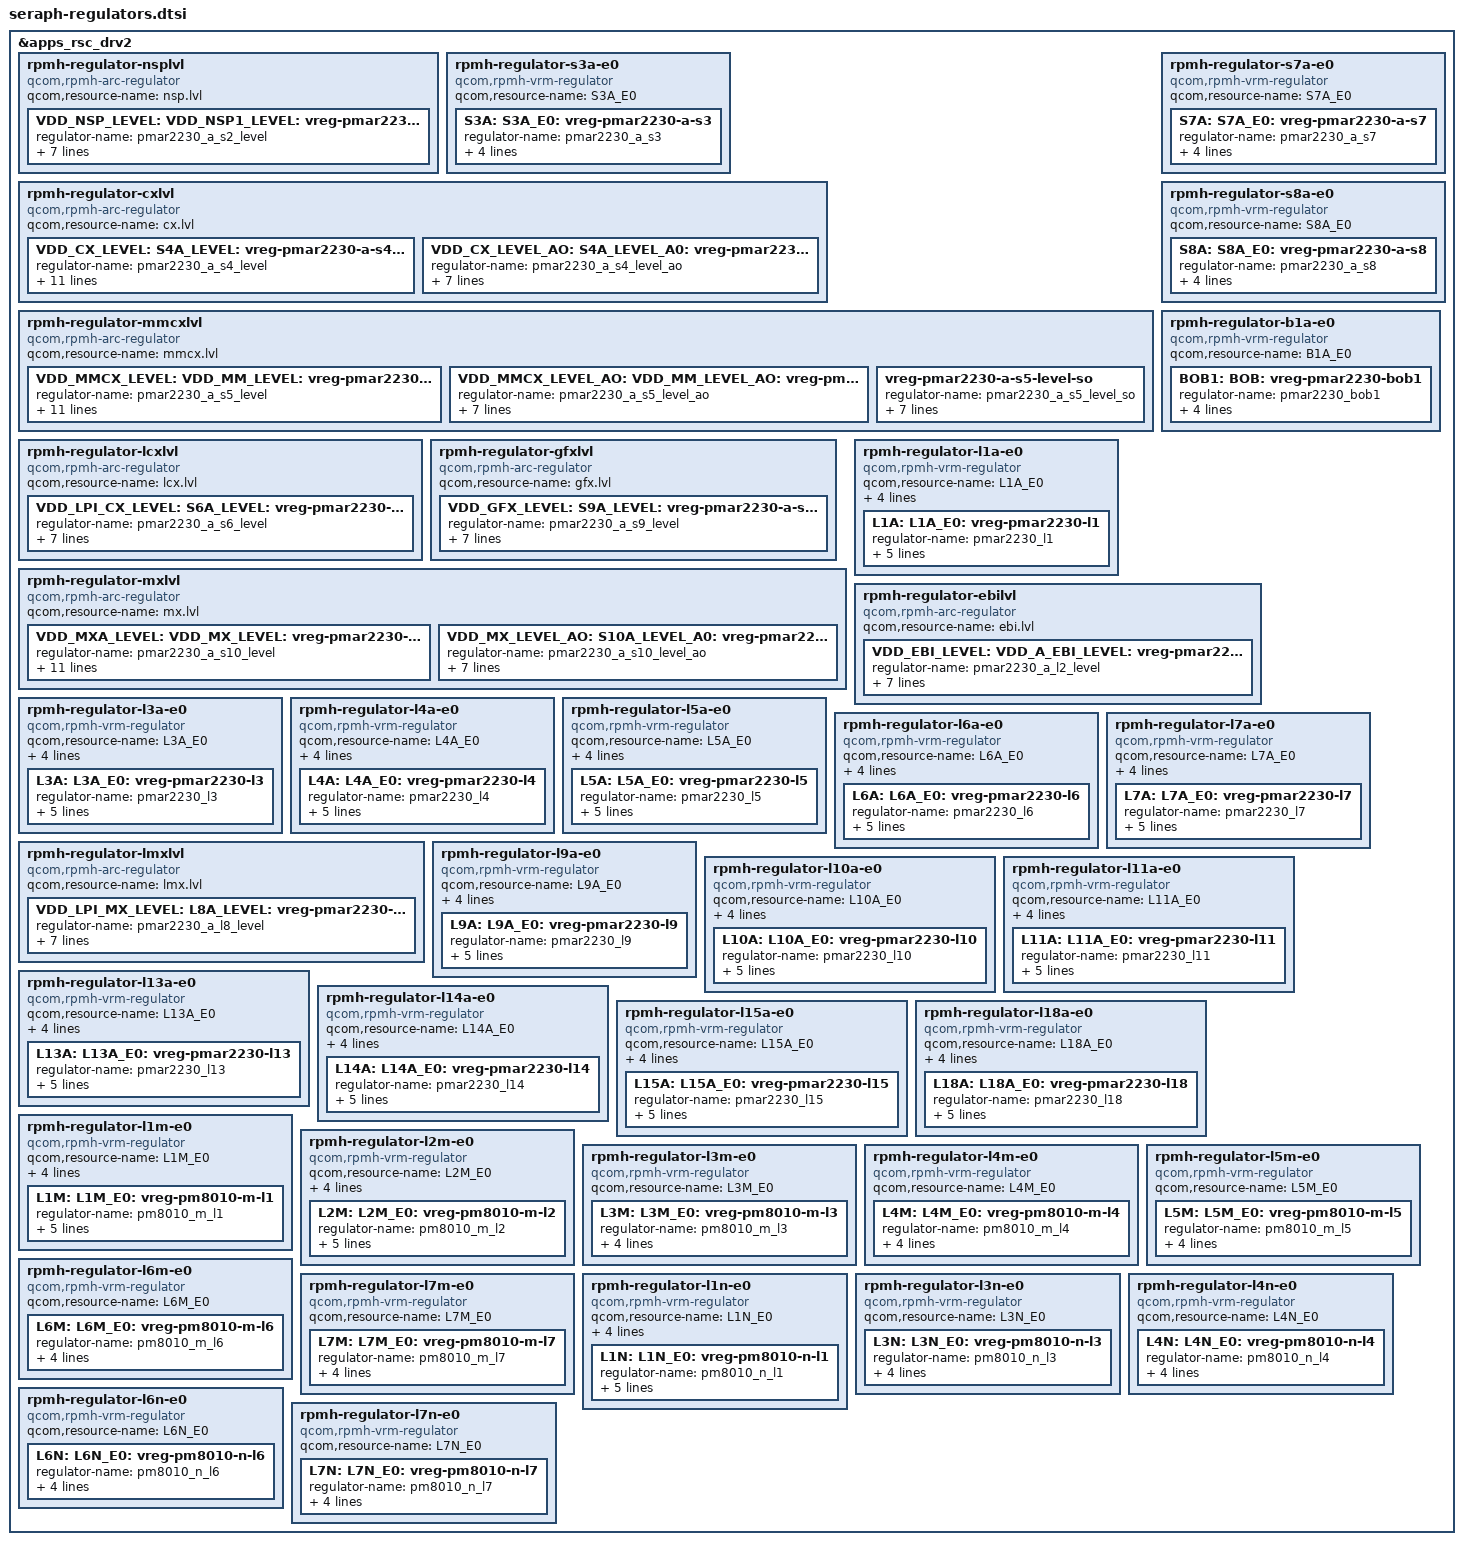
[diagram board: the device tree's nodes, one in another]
#include <dt-bindings/regulator/qcom,rpmh-regulator-levels.h>

&apps_rsc_drv2 {

	rpmh-regulator-nsplvl {
		compatible = "qcom,rpmh-arc-regulator";
		qcom,resource-name = "nsp.lvl";
		VDD_NSP_LEVEL:
		VDD_NSP1_LEVEL: S2A_LEVEL: S2A_E0_LEVEL:
		pmar2230_a_s2_level: vreg-pmar2230-a-s2-level {
			regulator-name = "pmar2230_a_s2_level";
			qcom,set = <RPMH_REGULATOR_SET_ALL>;
			regulator-min-microvolt =
				<RPMH_REGULATOR_LEVEL_RETENTION>;
			regulator-max-microvolt =
				<RPMH_REGULATOR_LEVEL_MAX>;
			qcom,init-voltage-level =
				<RPMH_REGULATOR_LEVEL_RETENTION>;
		};
	};

	rpmh-regulator-s3a-e0 {
		compatible = "qcom,rpmh-vrm-regulator";
		qcom,resource-name = "S3A_E0";
		S3A: S3A_E0:
		pmar2330_a_s3: vreg-pmar2230-a-s3 {
			regulator-name = "pmar2230_a_s3";
			qcom,set = <RPMH_REGULATOR_SET_ALL>;
			regulator-min-microvolt = <880000>;
			regulator-max-microvolt = <1080000>;
			qcom,init-voltage = <952000>;
		};
	};

	rpmh-regulator-cxlvl {
		compatible = "qcom,rpmh-arc-regulator";
		qcom,resource-name = "cx.lvl";
		VDD_CX_LEVEL:
		S4A_LEVEL: S4A_E0_LEVEL:
		pmar2230_a_s4_level: vreg-pmar2230-a-s4-level {
			regulator-name = "pmar2230_a_s4_level";
			qcom,set = <RPMH_REGULATOR_SET_ALL>;
			regulator-min-microvolt =
				<RPMH_REGULATOR_LEVEL_RETENTION>;
			regulator-max-microvolt =
				<RPMH_REGULATOR_LEVEL_MAX>;
			qcom,init-voltage-level =
				<RPMH_REGULATOR_LEVEL_TURBO>;
			proxy-supply = <&VDD_CX_LEVEL>;
			qcom,proxy-consumer-enable;
			qcom,proxy-consumer-voltage =
				<RPMH_REGULATOR_LEVEL_TURBO
				RPMH_REGULATOR_LEVEL_MAX>;
		};

		VDD_CX_LEVEL_AO:
		S4A_LEVEL_A0: S4A_E0_LEVEL_AO:
		pmar2230_a_s4_level_ao: vreg-pmar2230-a-s4-level-ao {
			regulator-name = "pmar2230_a_s4_level_ao";
			qcom,set = <RPMH_REGULATOR_SET_ACTIVE>;
			regulator-min-microvolt =
				<RPMH_REGULATOR_LEVEL_RETENTION>;
			regulator-max-microvolt =
				<RPMH_REGULATOR_LEVEL_MAX>;
			qcom,init-voltage-level =
				<RPMH_REGULATOR_LEVEL_RETENTION>;
		};
	};

	rpmh-regulator-mmcxlvl {
		compatible = "qcom,rpmh-arc-regulator";
		qcom,resource-name = "mmcx.lvl";
		VDD_MMCX_LEVEL: VDD_MM_LEVEL:
		S5A_LEVEL: S5A_E0_LEVEL:
		pmar2230_a_s5_level: vreg-pmar2230-a-s5-level {
			regulator-name = "pmar2230_a_s5_level";
			qcom,set = <RPMH_REGULATOR_SET_ALL>;
			regulator-min-microvolt =
				<RPMH_REGULATOR_LEVEL_LOW_SVS_D1>;
			regulator-max-microvolt =
				<RPMH_REGULATOR_LEVEL_MAX>;
			qcom,init-voltage-level =
				<RPMH_REGULATOR_LEVEL_TURBO>;
			proxy-supply = <&VDD_MMCX_LEVEL>;
			qcom,proxy-consumer-enable;
			qcom,proxy-consumer-voltage =
				<RPMH_REGULATOR_LEVEL_TURBO
				RPMH_REGULATOR_LEVEL_MAX>;
		};

		VDD_MMCX_LEVEL_AO: VDD_MM_LEVEL_AO:
		S5A_LEVEL_AO: S5A_E0_LEVEL_AO:
		pmar2230_a_s5_level_ao: vreg-pmar2230-a-s5-level-ao {
			regulator-name = "pmar2230_a_s5_level_ao";
			qcom,set = <RPMH_REGULATOR_SET_ACTIVE>;
			regulator-min-microvolt =
				<RPMH_REGULATOR_LEVEL_LOW_SVS_D1>;
			regulator-max-microvolt =
				<RPMH_REGULATOR_LEVEL_MAX>;
			qcom,init-voltage-level =
				<RPMH_REGULATOR_LEVEL_LOW_SVS_D1>;
		};

		vreg-pmar2230-a-s5-level-so {
			regulator-name = "pmar2230_a_s5_level_so";
			qcom,set = <RPMH_REGULATOR_SET_SLEEP>;
			regulator-min-microvolt =
				<RPMH_REGULATOR_LEVEL_LOW_SVS_D1>;
			regulator-max-microvolt =
				<RPMH_REGULATOR_LEVEL_MAX>;
			qcom,init-voltage-level =
				<RPMH_REGULATOR_LEVEL_LOW_SVS_D1>;
		};
	};

	rpmh-regulator-lcxlvl {
		compatible = "qcom,rpmh-arc-regulator";
		qcom,resource-name = "lcx.lvl";
		VDD_LPI_CX_LEVEL:
		S6A_LEVEL: S6A_E0_LEVEL:
		pmar2230_a_s6_level: vreg-pmar2230-a-s6-level {
			regulator-name = "pmar2230_a_s6_level";
			qcom,set = <RPMH_REGULATOR_SET_ALL>;
			regulator-min-microvolt =
				<RPMH_REGULATOR_LEVEL_RETENTION>;
			regulator-max-microvolt =
				<RPMH_REGULATOR_LEVEL_MAX>;
			qcom,init-voltage-level =
				<RPMH_REGULATOR_LEVEL_RETENTION>;
		};
	};

	rpmh-regulator-s7a-e0 {
		compatible = "qcom,rpmh-vrm-regulator";
		qcom,resource-name = "S7A_E0";
		S7A: S7A_E0:
		pmar2230_a_s7: vreg-pmar2230-a-s7 {
			regulator-name = "pmar2230_a_s7";
			qcom,set = <RPMH_REGULATOR_SET_ALL>;
			regulator-min-microvolt = <1852000>;
			regulator-max-microvolt = <2104000>;
			qcom,init-voltage = <1856000>;
		};
	};

	rpmh-regulator-s8a-e0 {
		compatible = "qcom,rpmh-vrm-regulator";
		qcom,resource-name = "S8A_E0";
		S8A: S8A_E0:
		pmar2230_a_s8: vreg-pmar2230-a-s8 {
			regulator-name = "pmar2230_a_s8";
			qcom,set = <RPMH_REGULATOR_SET_ALL>;
			regulator-min-microvolt = <1256000>;
			regulator-max-microvolt = <1408000>;
			qcom,init-voltage = <1304000>;
		};
	};

	rpmh-regulator-gfxlvl {
		compatible = "qcom,rpmh-arc-regulator";
		qcom,resource-name = "gfx.lvl";
		VDD_GFX_LEVEL:
		S9A_LEVEL: S9A_E0_LEVEL:
		pmar2230_a_s9_level: vreg-pmar2230-a-s9-level {
			regulator-name = "pmar2230_a_s9_level";
			qcom,set = <RPMH_REGULATOR_SET_ALL>;
			regulator-min-microvolt =
				<RPMH_REGULATOR_LEVEL_RETENTION>;
			regulator-max-microvolt =
				<RPMH_REGULATOR_LEVEL_MAX>;
			qcom,init-voltage-level =
				<RPMH_REGULATOR_LEVEL_RETENTION>;
		};
	};

	rpmh-regulator-mxlvl {
		compatible = "qcom,rpmh-arc-regulator";
		qcom,resource-name = "mx.lvl";
		VDD_MXA_LEVEL: VDD_MX_LEVEL:
		S10A_LEVEL: S10A_E0_LEVEL:
		pmar2230_a_s10_level: vreg-pmar2230-a-s10-level {
			regulator-name = "pmar2230_a_s10_level";
			qcom,set = <RPMH_REGULATOR_SET_ALL>;
			regulator-min-microvolt =
				<RPMH_REGULATOR_LEVEL_RETENTION>;
			regulator-max-microvolt =
				<RPMH_REGULATOR_LEVEL_MAX>;
			qcom,init-voltage-level =
				<RPMH_REGULATOR_LEVEL_TURBO>;
			proxy-supply = <&VDD_MXA_LEVEL>;
			qcom,proxy-consumer-enable;
			qcom,proxy-consumer-voltage =
				<RPMH_REGULATOR_LEVEL_TURBO
				RPMH_REGULATOR_LEVEL_MAX>;
		};

		VDD_MX_LEVEL_AO:
		S10A_LEVEL_A0: S10A_E0_LEVEL_AO:
		pmar2230_a_s10_level_ao: vreg-pmar2230-a-s10-level-ao {
			regulator-name = "pmar2230_a_s10_level_ao";
			qcom,set = <RPMH_REGULATOR_SET_ACTIVE>;
			regulator-min-microvolt =
				<RPMH_REGULATOR_LEVEL_RETENTION>;
			regulator-max-microvolt =
				<RPMH_REGULATOR_LEVEL_MAX>;
			qcom,init-voltage-level =
				<RPMH_REGULATOR_LEVEL_RETENTION>;
		};
	};

	rpmh-regulator-b1a-e0 {
		compatible = "qcom,rpmh-vrm-regulator";
		qcom,resource-name = "B1A_E0";

		BOB1: BOB: BOB1_E0: B1A_E0: pmar2230_bob1: vreg-pmar2230-bob1 {
			regulator-name = "pmar2230_bob1";
			qcom,set = <RPMH_REGULATOR_SET_ALL>;
			regulator-min-microvolt = <3008000>;
			regulator-max-microvolt = <3960000>;
			qcom,init-voltage = <3648000>;
		};
	};

	rpmh-regulator-l1a-e0 {
		compatible = "qcom,rpmh-vrm-regulator";
		qcom,resource-name = "L1A_E0";
		qcom,regulator-type = "pmic7-ldo";
		qcom,supported-modes =
			<RPMH_REGULATOR_MODE_LPM
			RPMH_REGULATOR_MODE_HPM>;
		qcom,mode-threshold-currents = <0 30000>;
		L1A: L1A_E0:
		pmar2230_l1: vreg-pmar2230-l1 {
			regulator-name = "pmar2230_l1";
			qcom,set = <RPMH_REGULATOR_SET_ALL>;
			regulator-min-microvolt = <320000>;
			regulator-max-microvolt = <570000>;
			qcom,init-voltage = <504000>;
			qcom,init-mode = <RPMH_REGULATOR_MODE_HPM>;
		};
	};

	rpmh-regulator-ebilvl {
		compatible = "qcom,rpmh-arc-regulator";
		qcom,resource-name = "ebi.lvl";
		VDD_EBI_LEVEL: VDD_A_EBI_LEVEL:
		L2A_LEVEL: L2A_E0_LEVEL:
		pmar2230_a_l2_level: vreg-pmar2230-a-l2-level {
			regulator-name = "pmar2230_a_l2_level";
			qcom,set = <RPMH_REGULATOR_SET_ALL>;
			regulator-min-microvolt =
				<RPMH_REGULATOR_LEVEL_RETENTION>;
			regulator-max-microvolt =
				<RPMH_REGULATOR_LEVEL_MAX>;
			qcom,init-voltage-level =
				<RPMH_REGULATOR_LEVEL_RETENTION>;
		};
	};

	rpmh-regulator-l3a-e0 {
		compatible = "qcom,rpmh-vrm-regulator";
		qcom,resource-name = "L3A_E0";
		qcom,regulator-type = "pmic7-ldo";
		qcom,supported-modes =
			<RPMH_REGULATOR_MODE_LPM
			RPMH_REGULATOR_MODE_HPM>;
		qcom,mode-threshold-currents = <0 30000>;
		L3A: L3A_E0:
		pmar2230_l3: vreg-pmar2230-l3 {
			regulator-name = "pmar2230_l3";
			qcom,set = <RPMH_REGULATOR_SET_ALL>;
			regulator-min-microvolt = <1080000>;
			regulator-max-microvolt = <2000000>;
			qcom,init-voltage = <1800000>;
			qcom,init-mode = <RPMH_REGULATOR_MODE_HPM>;
		};
	};

	rpmh-regulator-l4a-e0 {
		compatible = "qcom,rpmh-vrm-regulator";
		qcom,resource-name = "L4A_E0";
		qcom,regulator-type = "pmic7-ldo";
		qcom,supported-modes =
			<RPMH_REGULATOR_MODE_LPM
			RPMH_REGULATOR_MODE_AUTO>;
		qcom,mode-threshold-currents = <0 30000>;
		L4A: L4A_E0:
		pmar2230_l4: vreg-pmar2230-l4 {
			regulator-name = "pmar2230_l4";
			qcom,set = <RPMH_REGULATOR_SET_ALL>;
			regulator-min-microvolt = <1700000>;
			regulator-max-microvolt = <1950000>;
			qcom,init-voltage = <1800000>;
			qcom,init-mode = <RPMH_REGULATOR_MODE_HPM>;
		};
	};

	rpmh-regulator-l5a-e0 {
		compatible = "qcom,rpmh-vrm-regulator";
		qcom,resource-name = "L5A_E0";
		qcom,regulator-type = "pmic7-ldo";
		qcom,supported-modes =
			<RPMH_REGULATOR_MODE_LPM
			RPMH_REGULATOR_MODE_AUTO>;
		qcom,mode-threshold-currents = <0 30000>;
		L5A: L5A_E0:
		pmar2230_l5: vreg-pmar2230-l5 {
			regulator-name = "pmar2230_l5";
			qcom,set = <RPMH_REGULATOR_SET_ALL>;
			regulator-min-microvolt = <1080000>;
			regulator-max-microvolt = <1320000>;
			qcom,init-voltage = <1200000>;
			qcom,init-mode = <RPMH_REGULATOR_MODE_HPM>;
		};
	};

	rpmh-regulator-l6a-e0 {
		compatible = "qcom,rpmh-vrm-regulator";
		qcom,resource-name = "L6A_E0";
		qcom,regulator-type = "pmic7-ldo";
		qcom,supported-modes =
			<RPMH_REGULATOR_MODE_LPM
			RPMH_REGULATOR_MODE_AUTO>;
		qcom,mode-threshold-currents = <0 30000>;
		L6A: L6A_E0:
		pmar2230_l6: vreg-pmar2230-l6 {
			regulator-name = "pmar2230_l6";
			qcom,set = <RPMH_REGULATOR_SET_ALL>;
			regulator-min-microvolt = <1140000>;
			regulator-max-microvolt = <1260000>;
			qcom,init-voltage = <1200000>;
			qcom,init-mode = <RPMH_REGULATOR_MODE_HPM>;
		};
	};

	rpmh-regulator-l7a-e0 {
		compatible = "qcom,rpmh-vrm-regulator";
		qcom,resource-name = "L7A_E0";
		qcom,regulator-type = "pmic7-ldo";
		qcom,supported-modes =
			<RPMH_REGULATOR_MODE_LPM
			RPMH_REGULATOR_MODE_HPM>;
		qcom,mode-threshold-currents = <0 30000>;
		L7A: L7A_E0:
		pmar2230_l7: vreg-pmar2230-l7 {
			regulator-name = "pmar2230_l7";
			qcom,set = <RPMH_REGULATOR_SET_ALL>;
			regulator-min-microvolt = <1010000>;
			regulator-max-microvolt = <1120000>;
			qcom,init-voltage = <1080000>;
			qcom,init-mode = <RPMH_REGULATOR_MODE_HPM>;
		};
	};

	rpmh-regulator-lmxlvl {
		compatible = "qcom,rpmh-arc-regulator";
		qcom,resource-name = "lmx.lvl";
		VDD_LPI_MX_LEVEL:
		L8A_LEVEL: L8A_E0_LEVEL:
		pmar2230_a_l8_level: vreg-pmar2230-a-l8-level {
			regulator-name = "pmar2230_a_l8_level";
			qcom,set = <RPMH_REGULATOR_SET_ALL>;
			regulator-min-microvolt =
				<RPMH_REGULATOR_LEVEL_RETENTION>;
			regulator-max-microvolt =
				<RPMH_REGULATOR_LEVEL_MAX>;
			qcom,init-voltage-level =
				<RPMH_REGULATOR_LEVEL_RETENTION>;
		};
	};

	rpmh-regulator-l9a-e0 {
		compatible = "qcom,rpmh-vrm-regulator";
		qcom,resource-name = "L9A_E0";
		qcom,regulator-type = "pmic7-ldo";
		qcom,supported-modes =
			<RPMH_REGULATOR_MODE_LPM
			RPMH_REGULATOR_MODE_AUTO>;
		qcom,mode-threshold-currents = <0 30000>;
		L9A: L9A_E0:
		pmar2230_l9: vreg-pmar2230-l9 {
			regulator-name = "pmar2230_l9";
			qcom,set = <RPMH_REGULATOR_SET_ALL>;
			regulator-min-microvolt = <825000>;
			regulator-max-microvolt = <925000>;
			qcom,init-voltage = <880000>;
			qcom,init-mode = <RPMH_REGULATOR_MODE_HPM>;
		};
	};

	rpmh-regulator-l10a-e0 {
		compatible = "qcom,rpmh-vrm-regulator";
		qcom,resource-name = "L10A_E0";
		qcom,regulator-type = "pmic7-ldo";
		qcom,supported-modes =
			<RPMH_REGULATOR_MODE_LPM
			RPMH_REGULATOR_MODE_AUTO>;
		qcom,mode-threshold-currents = <0 30000>;
		L10A: L10A_E0:
		pmar2230_l10: vreg-pmar2230-l10 {
			regulator-name = "pmar2230_l10";
			qcom,set = <RPMH_REGULATOR_SET_ALL>;
			regulator-min-microvolt = <720000>;
			regulator-max-microvolt = <950000>;
			qcom,init-voltage = <880000>;
			qcom,init-mode = <RPMH_REGULATOR_MODE_HPM>;
		};
	};

	rpmh-regulator-l11a-e0 {
		compatible = "qcom,rpmh-vrm-regulator";
		qcom,resource-name = "L11A_E0";
		qcom,regulator-type = "pmic7-ldo";
		qcom,supported-modes =
			<RPMH_REGULATOR_MODE_LPM
			RPMH_REGULATOR_MODE_HPM>;
		qcom,mode-threshold-currents = <0 40000>;
		L11A: L11A_E0:
		pmar2230_l11: vreg-pmar2230-l11 {
			regulator-name = "pmar2230_l11";
			qcom,set = <RPMH_REGULATOR_SET_ALL>;
			regulator-min-microvolt = <2700000>;
			regulator-max-microvolt = <3544000>;
			qcom,init-voltage = <3304000>;
			qcom,init-mode = <RPMH_REGULATOR_MODE_HPM>;
		};
	};

	rpmh-regulator-l13a-e0 {
		compatible = "qcom,rpmh-vrm-regulator";
		qcom,resource-name = "L13A_E0";
		qcom,regulator-type = "pmic7-ldo";
		qcom,supported-modes =
			<RPMH_REGULATOR_MODE_LPM
			RPMH_REGULATOR_MODE_AUTO>;
		qcom,mode-threshold-currents = <0 30000>;
		L13A: L13A_E0:
		pmar2230_l13: vreg-pmar2230-l13 {
			regulator-name = "pmar2230_l13";
			qcom,set = <RPMH_REGULATOR_SET_ALL>;
			regulator-min-microvolt = <1100000>;
			regulator-max-microvolt = <1300000>;
			qcom,init-voltage = <1200000>;
			qcom,init-mode = <RPMH_REGULATOR_MODE_HPM>;
		};
	};

	rpmh-regulator-l14a-e0 {
		compatible = "qcom,rpmh-vrm-regulator";
		qcom,resource-name = "L14A_E0";
		qcom,regulator-type = "pmic7-ldo";
		qcom,supported-modes =
			<RPMH_REGULATOR_MODE_LPM
			RPMH_REGULATOR_MODE_AUTO>;
		qcom,mode-threshold-currents = <0 20000>;
		L14A: L14A_E0:
		pmar2230_l14: vreg-pmar2230-l14 {
			regulator-name = "pmar2230_l14";
			qcom,set = <RPMH_REGULATOR_SET_ALL>;
			regulator-min-microvolt = <2850000>;
			regulator-max-microvolt = <3544000>;
			qcom,init-voltage = <3000000>;
			qcom,init-mode = <RPMH_REGULATOR_MODE_HPM>;
		};
	};

	rpmh-regulator-l15a-e0 {
		compatible = "qcom,rpmh-vrm-regulator";
		qcom,resource-name = "L15A_E0";
		qcom,regulator-type = "pmic7-ldo";
		qcom,supported-modes =
			<RPMH_REGULATOR_MODE_LPM
			RPMH_REGULATOR_MODE_HPM>;
		qcom,mode-threshold-currents = <0 30000>;
		L15A: L15A_E0:
		pmar2230_l15: vreg-pmar2230-l15 {
			regulator-name = "pmar2230_l15";
			qcom,set = <RPMH_REGULATOR_SET_ALL>;
			regulator-min-microvolt = <870000>;
			regulator-max-microvolt = <970000>;
			qcom,init-voltage = <904000>;
			qcom,init-mode = <RPMH_REGULATOR_MODE_HPM>;
		};
	};

	rpmh-regulator-l18a-e0 {
		compatible = "qcom,rpmh-vrm-regulator";
		qcom,resource-name = "L18A_E0";
		qcom,regulator-type = "pmic7-ldo";
		qcom,supported-modes =
			<RPMH_REGULATOR_MODE_LPM
			RPMH_REGULATOR_MODE_AUTO>;
		qcom,mode-threshold-currents = <0 30000>;
		L18A: L18A_E0:
		pmar2230_l18: vreg-pmar2230-l18 {
			regulator-name = "pmar2230_l18";
			qcom,set = <RPMH_REGULATOR_SET_ALL>;
			regulator-min-microvolt = <1620000>;
			regulator-max-microvolt = <2000000>;
			qcom,init-voltage = <1800000>;
			qcom,init-mode = <RPMH_REGULATOR_MODE_HPM>;
		};
	};

	rpmh-regulator-l1m-e0 {
		compatible = "qcom,rpmh-vrm-regulator";
		qcom,resource-name = "L1M_E0";
		qcom,regulator-type = "pmic5-ldo";
		qcom,supported-modes =
			<RPMH_REGULATOR_MODE_LPM
			RPMH_REGULATOR_MODE_HPM>;
		qcom,mode-threshold-currents = <0 100000>;
		L1M: L1M_E0:
		pm8010_m_l1: vreg-pm8010-m-l1 {
			regulator-name = "pm8010_m_l1";
			qcom,set = <RPMH_REGULATOR_SET_ALL>;
			regulator-min-microvolt = <1140000>;
			regulator-max-microvolt = <1260000>;
			qcom,init-voltage = <1140000>;
			qcom,init-mode = <RPMH_REGULATOR_MODE_HPM>;
		};
	};

	rpmh-regulator-l2m-e0 {
		compatible = "qcom,rpmh-vrm-regulator";
		qcom,resource-name = "L2M_E0";
		qcom,regulator-type = "pmic5-ldo";
		qcom,supported-modes =
			<RPMH_REGULATOR_MODE_LPM
			RPMH_REGULATOR_MODE_HPM>;
		qcom,mode-threshold-currents = <0 100000>;
		L2M: L2M_E0:
		pm8010_m_l2: vreg-pm8010-m-l2 {
			regulator-name = "pm8010_m_l2";
			qcom,set = <RPMH_REGULATOR_SET_ALL>;
			regulator-min-microvolt = <950000>;
			regulator-max-microvolt = <1150000>;
			qcom,init-voltage = <950000>;
			qcom,init-mode = <RPMH_REGULATOR_MODE_HPM>;
		};
	};

	rpmh-regulator-l3m-e0 {
		compatible = "qcom,rpmh-vrm-regulator";
		qcom,resource-name = "L3M_E0";
		L3M: L3M_E0:
		pm8010_m_l3: vreg-pm8010-m-l3 {
			regulator-name = "pm8010_m_l3";
			qcom,set = <RPMH_REGULATOR_SET_ALL>;
			regulator-min-microvolt = <1792000>;
			regulator-max-microvolt = <1900000>;
			qcom,init-voltage = <1792000>;
		};
	};

	rpmh-regulator-l4m-e0 {
		compatible = "qcom,rpmh-vrm-regulator";
		qcom,resource-name = "L4M_E0";
		L4M: L4M_E0:
		pm8010_m_l4: vreg-pm8010-m-l4 {
			regulator-name = "pm8010_m_l4";
			qcom,set = <RPMH_REGULATOR_SET_ALL>;
			regulator-min-microvolt = <1792000>;
			regulator-max-microvolt = <1900000>;
			qcom,init-voltage = <1792000>;
		};
	};

	rpmh-regulator-l5m-e0 {
		compatible = "qcom,rpmh-vrm-regulator";
		qcom,resource-name = "L5M_E0";
		L5M: L5M_E0:
		pm8010_m_l5: vreg-pm8010-m-l5 {
			regulator-name = "pm8010_m_l5";
			qcom,set = <RPMH_REGULATOR_SET_ALL>;
			regulator-min-microvolt = <2600000>;
			regulator-max-microvolt = <3000000>;
			qcom,init-voltage = <2600000>;
		};
	};

	rpmh-regulator-l6m-e0 {
		compatible = "qcom,rpmh-vrm-regulator";
		qcom,resource-name = "L6M_E0";
		L6M: L6M_E0:
		pm8010_m_l6: vreg-pm8010-m-l6 {
			regulator-name = "pm8010_m_l6";
			qcom,set = <RPMH_REGULATOR_SET_ALL>;
			regulator-min-microvolt = <2700000>;
			regulator-max-microvolt = <2900000>;
			qcom,init-voltage = <2700000>;
		};
	};

	rpmh-regulator-l7m-e0 {
		compatible = "qcom,rpmh-vrm-regulator";
		qcom,resource-name = "L7M_E0";
		L7M: L7M_E0:
		pm8010_m_l7: vreg-pm8010-m-l7 {
			regulator-name = "pm8010_m_l7";
			qcom,set = <RPMH_REGULATOR_SET_ALL>;
			regulator-min-microvolt = <2600000>;
			regulator-max-microvolt = <3000000>;
			qcom,init-voltage = <2600000>;
		};
	};

	rpmh-regulator-l1n-e0 {
		compatible = "qcom,rpmh-vrm-regulator";
		qcom,resource-name = "L1N_E0";
		qcom,regulator-type = "pmic5-ldo";
		qcom,supported-modes =
			<RPMH_REGULATOR_MODE_LPM
			RPMH_REGULATOR_MODE_HPM>;
		qcom,mode-threshold-currents = <0 100000>;
		L1N: L1N_E0:
		pm8010_n_l1: vreg-pm8010-n-l1 {
			regulator-name = "pm8010_n_l1";
			qcom,set = <RPMH_REGULATOR_SET_ALL>;
			regulator-min-microvolt = <1000000>;
			regulator-max-microvolt = <1200000>;
			qcom,init-voltage = <1000000>;
			qcom,init-mode = <RPMH_REGULATOR_MODE_HPM>;
		};
	};

	rpmh-regulator-l3n-e0 {
		compatible = "qcom,rpmh-vrm-regulator";
		qcom,resource-name = "L3N_E0";
		L3N: L3N_E0:
		pm8010_n_l3: vreg-pm8010-n-l3 {
			regulator-name = "pm8010_n_l3";
			qcom,set = <RPMH_REGULATOR_SET_ALL>;
			regulator-min-microvolt = <2700000>;
			regulator-max-microvolt = <3000000>;
			qcom,init-voltage = <2700000>;
		};
	};

	rpmh-regulator-l4n-e0 {
		compatible = "qcom,rpmh-vrm-regulator";
		qcom,resource-name = "L4N_E0";
		L4N: L4N_E0:
		pm8010_n_l4: vreg-pm8010-n-l4 {
			regulator-name = "pm8010_n_l4";
			qcom,set = <RPMH_REGULATOR_SET_ALL>;
			regulator-min-microvolt = <2700000>;
			regulator-max-microvolt = <3000000>;
			qcom,init-voltage = <2700000>;
		};
	};

	rpmh-regulator-l6n-e0 {
		compatible = "qcom,rpmh-vrm-regulator";
		qcom,resource-name = "L6N_E0";
		L6N: L6N_E0:
		pm8010_n_l6: vreg-pm8010-n-l6 {
			regulator-name = "pm8010_n_l6";
			qcom,set = <RPMH_REGULATOR_SET_ALL>;
			regulator-min-microvolt = <2900000>;
			regulator-max-microvolt = <3100000>;
			qcom,init-voltage = <2900000>;
		};
	};

	rpmh-regulator-l7n-e0 {
		compatible = "qcom,rpmh-vrm-regulator";
		qcom,resource-name = "L7N_E0";
		L7N: L7N_E0:
		pm8010_n_l7: vreg-pm8010-n-l7 {
			regulator-name = "pm8010_n_l7";
			qcom,set = <RPMH_REGULATOR_SET_ALL>;
			regulator-min-microvolt = <3200000>;
			regulator-max-microvolt = <3300000>;
			qcom,init-voltage = <3200000>;
		};
	};
};
